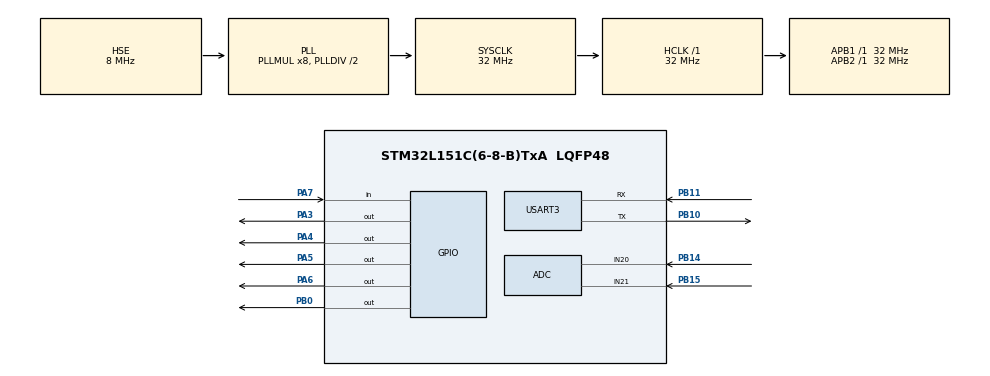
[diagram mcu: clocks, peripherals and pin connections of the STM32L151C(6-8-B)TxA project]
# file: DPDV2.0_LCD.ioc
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ADC.Channel-0\#ChannelRegularConversion=ADC_CHANNEL_20
ADC.NbrOfConversionFlag=1
ADC.Rank-0\#ChannelRegularConversion=1
ADC.SamplingTime-0\#ChannelRegularConversion=ADC_SAMPLETIME_4CYCLES
Mcu.Family=STM32L1
Mcu.Name=STM32L151C(6-8-B)TxA
Mcu.Package=LQFP48
NVIC.PriorityGroup=NVIC_PRIORITYGROUP_4
NVIC.TIM2_IRQn=true\:0\:0\:false\:false\:true\:true
NVIC.USART3_IRQn=true\:0\:0\:false\:false\:true\:true
PA3.GPIO_PuPd=GPIO_PULLUP
PA3.GPIO_Speed=GPIO_SPEED_FREQ_VERY_HIGH
PA3.PinState=GPIO_PIN_SET
PA3.Signal=GPIO_Output
PA4.GPIO_PuPd=GPIO_PULLUP
PA4.GPIO_Speed=GPIO_SPEED_FREQ_VERY_HIGH
PA4.PinState=GPIO_PIN_SET
PA4.Signal=GPIO_Output
PA5.GPIO_PuPd=GPIO_PULLUP
PA5.GPIO_Speed=GPIO_SPEED_FREQ_VERY_HIGH
PA5.PinState=GPIO_PIN_SET
PA5.Signal=GPIO_Output
PA6.GPIO_PuPd=GPIO_PULLUP
PA6.GPIO_Speed=GPIO_SPEED_FREQ_VERY_HIGH
PA6.PinState=GPIO_PIN_SET
PA6.Signal=GPIO_Output
PA7.GPIO_PuPd=GPIO_PULLDOWN
PA7.Signal=GPIO_Input
PB0.GPIO_PuPd=GPIO_PULLUP
PB0.GPIO_Speed=GPIO_SPEED_FREQ_VERY_HIGH
PB0.PinState=GPIO_PIN_SET
PB0.Signal=GPIO_Output
PB10.Mode=Asynchronous
PB10.Signal=USART3_TX
PB11.Mode=Asynchronous
PB11.Signal=USART3_RX
PB14.Mode=IN20
PB14.Signal=ADC_IN20
PB15.Mode=IN21
PB15.Signal=ADC_IN21
PH0-OSC_IN.Mode=HSE-External-Oscillator
PH0-OSC_IN.Signal=RCC_OSC_IN
PH1-OSC_OUT.Mode=HSE-External-Oscillator
PH1-OSC_OUT.Signal=RCC_OSC_OUT
ProjectManager.HeapSize=0x200
ProjectManager.StackSize=0x400
ProjectManager.TargetToolchain=MDK-ARM V5
RCC.48MHZClocksFreq_Value=32000000
RCC.AHBFreq_Value=32000000
RCC.APB1Freq_Value=32000000
RCC.APB1TimFreq_Value=32000000
RCC.APB2Freq_Value=32000000
RCC.APB2TimFreq_Value=32000000
RCC.HCLKFreq_Value=32000000
RCC.HSE_VALUE=8000000
RCC.HSI_VALUE=16000000
RCC.LSE_VALUE=32768
RCC.MSI_VALUE=2097000
RCC.PLLMUL=RCC_PLL_MUL8
RCC.PLLSourceVirtual=RCC_PLLSOURCE_HSE
RCC.SYSCLKFreq_VALUE=32000000
RCC.SYSCLKSource=RCC_SYSCLKSOURCE_PLLCLK
RCC.VCOOutputFreq_Value=64000000
TIM2.Period=39
TIM2.Prescaler=7
USART3.VirtualMode=VM_ASYNC
VP_TIM2_VS_ClockSourceINT.Mode=Internal
board=custom

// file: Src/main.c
/**
  ******************************************************************************
  * @file           : main.c
  * @brief          : Main program body
  ******************************************************************************
  ** This notice applies to any and all portions of this file
  * that are not between comment pairs USER CODE BEGIN and
  * USER CODE END. Other portions of this file, whether
  * inserted by the user or by software development tools
  * are owned by their respective copyright owners.
  *
  * COPYRIGHT(c) 2018 STMicroelectronics
  *
  * Redistribution and use in source and binary forms, with or without modification,
  * are permitted provided that the following conditions are met:
  *   1. Redistributions of source code must retain the above copyright notice,
  *      this list of conditions and the following disclaimer.
  *   2. Redistributions in binary form must reproduce the above copyright notice,
  *      this list of conditions and the following disclaimer in the documentation
  *      and/or other materials provided with the distribution.
  *   3. Neither the name of STMicroelectronics nor the names of its contributors
  *      may be used to endorse or promote products derived from this software
  *      without specific prior written permission.
  *
  * THIS SOFTWARE IS PROVIDED BY THE COPYRIGHT HOLDERS AND CONTRIBUTORS "AS IS"
  * AND ANY EXPRESS OR IMPLIED WARRANTIES, INCLUDING, BUT NOT LIMITED TO, THE
  * IMPLIED WARRANTIES OF MERCHANTABILITY AND FITNESS FOR A PARTICULAR PURPOSE ARE
  * DISCLAIMED. IN NO EVENT SHALL THE COPYRIGHT HOLDER OR CONTRIBUTORS BE LIABLE
  * FOR ANY DIRECT, INDIRECT, INCIDENTAL, SPECIAL, EXEMPLARY, OR CONSEQUENTIAL
  * DAMAGES (INCLUDING, BUT NOT LIMITED TO, PROCUREMENT OF SUBSTITUTE GOODS OR
  * SERVICES; LOSS OF USE, DATA, OR PROFITS; OR BUSINESS INTERRUPTION) HOWEVER
  * CAUSED AND ON ANY THEORY OF LIABILITY, WHETHER IN CONTRACT, STRICT LIABILITY,
  * OR TORT (INCLUDING NEGLIGENCE OR OTHERWISE) ARISING IN ANY WAY OUT OF THE USE
  * OF THIS SOFTWARE, EVEN IF ADVISED OF THE POSSIBILITY OF SUCH DAMAGE.
  *
  ******************************************************************************
  */
#include "main.h"
#include "stm32l1xx_hal.h"
#include "adc.h"
#include "tim.h"
#include "usart.h"
#include "gpio.h"

/* USER CODE BEGIN Includes */
#include "lcd.h"
/* USER CODE END Includes */

/* USER CODE BEGIN PV */
/* Private variables ---------------------------------------------------------*/

/* USER CODE END PV */

void SystemClock_Config(void);

/* USER CODE BEGIN PFP */
/* Private function prototypes -----------------------------------------------*/

/* USER CODE END PFP */

int main(void)
{

  /* MCU Configuration----------------------------------------------------------*/

  /* Reset of all peripherals, Initializes the Flash interface and the Systick. */
  HAL_Init();

  /* Configure the system clock */
  SystemClock_Config();

  /* Initialize all configured peripherals */
  MX_GPIO_Init();

  MX_USART3_UART_Init();
  MX_ADC_Init();
  /* USER CODE BEGIN 2 */
  lcd_init();
  lcd_turnOnShow();//开机动画
//	lcd_showBeforeLcdSleep(2);//清屏显示电池电量

  lcd_showFourNumBy16X32DM(1234567);
  MX_TIM2_Init();
  /* USER CODE END 2 */

  /* Infinite loop */
  /* USER CODE BEGIN WHILE */
  while (1)
  {
//HAL_UART_Transmit(&huart3,stopTimBroadcast,1,100);
//HAL_Delay(1000);
  /* USER CODE END WHILE */

  }

}

void SystemClock_Config(void)
{

  RCC_OscInitTypeDef RCC_OscInitStruct;
  RCC_ClkInitTypeDef RCC_ClkInitStruct;

    /**Configure the main internal regulator output voltage
    */
  __HAL_PWR_VOLTAGESCALING_CONFIG(PWR_REGULATOR_VOLTAGE_SCALE1);

    /**Initializes the CPU, AHB and APB busses clocks
    */
  RCC_OscInitStruct.OscillatorType = RCC_OSCILLATORTYPE_HSI|RCC_OSCILLATORTYPE_HSE;
  RCC_OscInitStruct.HSEState = RCC_HSE_ON;
  RCC_OscInitStruct.HSIState = RCC_HSI_ON;
  RCC_OscInitStruct.HSICalibrationValue = 16;
  RCC_OscInitStruct.PLL.PLLState = RCC_PLL_ON;
  RCC_OscInitStruct.PLL.PLLSource = RCC_PLLSOURCE_HSE;
  RCC_OscInitStruct.PLL.PLLMUL = RCC_PLL_MUL8;
  RCC_OscInitStruct.PLL.PLLDIV = RCC_PLL_DIV2;
  if (HAL_RCC_OscConfig(&RCC_OscInitStruct) != HAL_OK)
  {
    _Error_Handler(__FILE__, __LINE__);
  }

    /**Initializes the CPU, AHB and APB busses clocks
    */
  RCC_ClkInitStruct.ClockType = RCC_CLOCKTYPE_HCLK|RCC_CLOCKTYPE_SYSCLK
                              |RCC_CLOCKTYPE_PCLK1|RCC_CLOCKTYPE_PCLK2;
  RCC_ClkInitStruct.SYSCLKSource = RCC_SYSCLKSOURCE_PLLCLK;
  RCC_ClkInitStruct.AHBCLKDivider = RCC_SYSCLK_DIV1;
  RCC_ClkInitStruct.APB1CLKDivider = RCC_HCLK_DIV1;
  RCC_ClkInitStruct.APB2CLKDivider = RCC_HCLK_DIV1;

  if (HAL_RCC_ClockConfig(&RCC_ClkInitStruct, FLASH_LATENCY_1) != HAL_OK)
  {
    _Error_Handler(__FILE__, __LINE__);
  }

    /**Configure the Systick interrupt time
    */
  HAL_SYSTICK_Config(HAL_RCC_GetHCLKFreq()/1000);

    /**Configure the Systick
    */
  HAL_SYSTICK_CLKSourceConfig(SYSTICK_CLKSOURCE_HCLK);

  /* SysTick_IRQn interrupt configuration */
  HAL_NVIC_SetPriority(SysTick_IRQn, 0, 0);
}

void _Error_Handler(char *file, int line)
{
  while(1)
  {
  }
}

/************************ (C) COPYRIGHT STMicroelectronics *****END OF FILE****/
